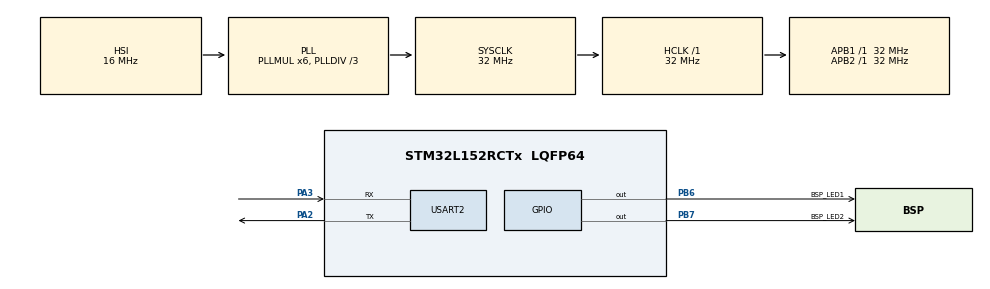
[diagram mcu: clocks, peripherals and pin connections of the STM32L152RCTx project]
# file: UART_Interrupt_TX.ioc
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Mcu.Family=STM32L1
Mcu.Name=STM32L152RCTx
Mcu.Package=LQFP64
NVIC.PriorityGroup=NVIC_PRIORITYGROUP_0
NVIC.USART2_IRQn=true\:0\:0\:false\:false\:true\:true\:true\:true
PA2.Mode=Asynchronous
PA2.Signal=USART2_TX
PA3.Mode=Asynchronous
PA3.Signal=USART2_RX
PB6.GPIO_Label=BSP_LED1
PB6.Signal=GPIO_Output
PB7.GPIO_Label=BSP_LED2
PB7.Signal=GPIO_Output
ProjectManager.HeapSize=0x200
ProjectManager.StackSize=0x400
ProjectManager.TargetToolchain=STM32CubeIDE
RCC.48MHZClocksFreq_Value=48000000
RCC.AHBFreq_Value=32000000
RCC.APB1Freq_Value=32000000
RCC.APB1TimFreq_Value=32000000
RCC.APB2Freq_Value=32000000
RCC.APB2TimFreq_Value=32000000
RCC.HCLKFreq_Value=32000000
RCC.HSE_VALUE=8000000
RCC.HSI_VALUE=16000000
RCC.MSI_VALUE=2097000
RCC.PLLDIV=RCC_PLL_DIV3
RCC.PLLMUL=RCC_PLL_MUL6
RCC.RTCClockSelectionVirtual=RCC_RTCCLKSOURCE_LSE
RCC.SYSCLKFreq_VALUE=32000000
RCC.SYSCLKSource=RCC_SYSCLKSOURCE_PLLCLK
RCC.USBOutput=48000000
RCC.VCOOutputFreq_Value=96000000
USART2.VirtualMode=VM_ASYNC
board=STM32L152C-DISCO

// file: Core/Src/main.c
/* USER CODE BEGIN Header */
/**
 ******************************************************************************
 * @file           : main.c
 * @brief          : Main program body
 ******************************************************************************
 * @attention
 *
 * Copyright (c) 2023 STMicroelectronics.
 * All rights reserved.
 *
 * This software is licensed under terms that can be found in the LICENSE file
 * in the root directory of this software component.
 * If no LICENSE file comes with this software, it is provided AS-IS.
 *
 ******************************************************************************
 */
/* USER CODE END Header */
#include "main.h"

UART_HandleTypeDef huart2;

void SystemClock_Config(void);
static void MX_GPIO_Init(void);
static void MX_USART2_UART_Init(void);
/* USER CODE BEGIN PFP */
unsigned char data[]="jadavhiren\r\n";
unsigned char rx_data[50];

void HAL_UART_RxCpltCallback(UART_HandleTypeDef *huart) {

	HAL_UART_Receive_IT(&huart2, rx_data, 10);
	HAL_UART_Transmit_IT(&huart2, rx_data, 10);
}
/* USER CODE END PFP */

int main(void) {

	/* MCU Configuration--------------------------------------------------------*/

	/* Reset of all peripherals, Initializes the Flash interface and the Systick. */
	HAL_Init();

	/* Configure the system clock */
	SystemClock_Config();

	/* Initialize all configured peripherals */
	MX_GPIO_Init();
	MX_USART2_UART_Init();
	/* USER CODE BEGIN 2 */
	 // this intruppt method tx
	HAL_UART_Receive_IT(&huart2, rx_data, 10);

	/* USER CODE END 2 */

	/* Infinite loop */
	while (1) {
		HAL_GPIO_TogglePin(BSP_LED1_GPIO_Port, BSP_LED1_Pin);
		HAL_Delay(500);

//		HAL_Delay(500);

	}
}

void SystemClock_Config(void) {
	RCC_OscInitTypeDef RCC_OscInitStruct = { 0 };
	RCC_ClkInitTypeDef RCC_ClkInitStruct = { 0 };

	/** Configure the main internal regulator output voltage
	 */
	__HAL_PWR_VOLTAGESCALING_CONFIG(PWR_REGULATOR_VOLTAGE_SCALE1);

	/** Initializes the RCC Oscillators according to the specified parameters
	 * in the RCC_OscInitTypeDef structure.
	 */
	RCC_OscInitStruct.OscillatorType = RCC_OSCILLATORTYPE_HSI;
	RCC_OscInitStruct.HSIState = RCC_HSI_ON;
	RCC_OscInitStruct.HSICalibrationValue = RCC_HSICALIBRATION_DEFAULT;
	RCC_OscInitStruct.PLL.PLLState = RCC_PLL_ON;
	RCC_OscInitStruct.PLL.PLLSource = RCC_PLLSOURCE_HSI;
	RCC_OscInitStruct.PLL.PLLMUL = RCC_PLL_MUL6;
	RCC_OscInitStruct.PLL.PLLDIV = RCC_PLL_DIV3;
	if (HAL_RCC_OscConfig(&RCC_OscInitStruct) != HAL_OK) {
		Error_Handler();
	}

	/** Initializes the CPU, AHB and APB buses clocks
	 */
	RCC_ClkInitStruct.ClockType = RCC_CLOCKTYPE_HCLK | RCC_CLOCKTYPE_SYSCLK
			| RCC_CLOCKTYPE_PCLK1 | RCC_CLOCKTYPE_PCLK2;
	RCC_ClkInitStruct.SYSCLKSource = RCC_SYSCLKSOURCE_PLLCLK;
	RCC_ClkInitStruct.AHBCLKDivider = RCC_SYSCLK_DIV1;
	RCC_ClkInitStruct.APB1CLKDivider = RCC_HCLK_DIV1;
	RCC_ClkInitStruct.APB2CLKDivider = RCC_HCLK_DIV1;

	if (HAL_RCC_ClockConfig(&RCC_ClkInitStruct, FLASH_LATENCY_1) != HAL_OK) {
		Error_Handler();
	}
}

static void MX_USART2_UART_Init(void) {

	huart2.Instance = USART2;
	huart2.Init.BaudRate = 115200;
	huart2.Init.WordLength = UART_WORDLENGTH_8B;
	huart2.Init.StopBits = UART_STOPBITS_1;
	huart2.Init.Parity = UART_PARITY_NONE;
	huart2.Init.Mode = UART_MODE_TX_RX;
	huart2.Init.HwFlowCtl = UART_HWCONTROL_NONE;
	huart2.Init.OverSampling = UART_OVERSAMPLING_16;
	if (HAL_UART_Init(&huart2) != HAL_OK) {
		Error_Handler();
	}

}

static void MX_GPIO_Init(void) {
	GPIO_InitTypeDef GPIO_InitStruct = { 0 };

	/* GPIO Ports Clock Enable */
	__HAL_RCC_GPIOA_CLK_ENABLE();
	__HAL_RCC_GPIOB_CLK_ENABLE();

	/*Configure GPIO pin Output Level */
	HAL_GPIO_WritePin(GPIOB, BSP_LED1_Pin | BSP_LED2_Pin, GPIO_PIN_RESET);

	/*Configure GPIO pins : BSP_LED1_Pin BSP_LED2_Pin */
	GPIO_InitStruct.Pin = BSP_LED1_Pin | BSP_LED2_Pin;
	GPIO_InitStruct.Mode = GPIO_MODE_OUTPUT_PP;
	GPIO_InitStruct.Pull = GPIO_NOPULL;
	GPIO_InitStruct.Speed = GPIO_SPEED_FREQ_LOW;
	HAL_GPIO_Init(GPIOB, &GPIO_InitStruct);

}

void Error_Handler(void) {
	__disable_irq();
	while (1) {
	}
}
